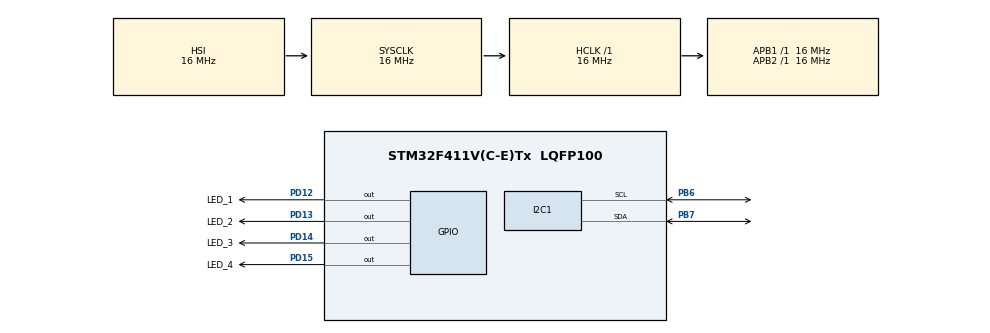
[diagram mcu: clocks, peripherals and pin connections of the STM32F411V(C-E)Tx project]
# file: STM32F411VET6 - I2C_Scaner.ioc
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Mcu.Family=STM32F4
Mcu.Name=STM32F411V(C-E)Tx
Mcu.Package=LQFP100
NVIC.PriorityGroup=NVIC_PRIORITYGROUP_4
PA13.Mode=Serial_Wire
PA13.Signal=SYS_JTMS-SWDIO
PA14.Mode=Serial_Wire
PA14.Signal=SYS_JTCK-SWCLK
PB6.Mode=I2C
PB6.Signal=I2C1_SCL
PB7.Mode=I2C
PB7.Signal=I2C1_SDA
PD12.GPIO_Label=LED_1
PD12.Signal=GPIO_Output
PD13.GPIO_Label=LED_2
PD13.Signal=GPIO_Output
PD14.GPIO_Label=LED_3
PD14.Signal=GPIO_Output
PD15.GPIO_Label=LED_4
PD15.Signal=GPIO_Output
ProjectManager.HeapSize=0x200
ProjectManager.StackSize=0x400
ProjectManager.TargetToolchain=STM32CubeIDE
RCC.AHBFreq_Value=16000000
RCC.APB1Freq_Value=16000000
RCC.APB2Freq_Value=16000000
RCC.CortexFreq_Value=16000000
RCC.HSE_VALUE=25000000
RCC.HSI_VALUE=16000000
RCC.LSE_VALUE=32768
RCC.SYSCLKFreq_VALUE=16000000
RCC.VCOOutputFreq_Value=192000000
board=custom

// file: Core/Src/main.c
/* USER CODE BEGIN Header */
/**
  ******************************************************************************
  * @file           : main.c
  * @brief          : Main program body
  ******************************************************************************
  * @attention
  *
  * Copyright (c) 2024 STMicroelectronics.
  * All rights reserved.
  *
  * This software is licensed under terms that can be found in the LICENSE file
  * in the root directory of this software component.
  * If no LICENSE file comes with this software, it is provided AS-IS.
  *
  ******************************************************************************
  */
/* USER CODE END Header */
#include "main.h"
#include "i2c.h"
#include "gpio.h"

/* USER CODE BEGIN PD */
//#define BMP280_ADDRESS 0x76
/* USER CODE END PD */

/* USER CODE BEGIN PV */

uint8_t Adress;
/* USER CODE END PV */

void SystemClock_Config(void);

int main(void)
{

  /* MCU Configuration--------------------------------------------------------*/

  /* Reset of all peripherals, Initializes the Flash interface and the Systick. */
  HAL_Init();

  /* Configure the system clock */
  SystemClock_Config();

  /* Initialize all configured peripherals */
  MX_GPIO_Init();
  MX_I2C1_Init();
  /* USER CODE BEGIN 2 */
  //BMP280_Init(&Bmp280, &hi2c1, BMP280_ADDRESS);
  //float Temp, Pressure;

	HAL_StatusTypeDef result;
   	uint8_t i;
   	for (i=1; i<128; i++)
   	{
   	  /*
   	   * the HAL wants a left aligned i2c address
   	   * &hi2c1 is the handle
   	   * (uint16_t)(i<<1) is the i2c address left aligned
   	   * retries 2
   	   * timeout 2
   	   */
   	  result = HAL_I2C_IsDeviceReady(&hi2c1, (uint16_t)(i<<1), 2, 2);
   	  if (result != HAL_OK) // HAL_ERROR or HAL_BUSY or HAL_TIMEOUT
   	  {
   		 HAL_GPIO_TogglePin(LED_1_GPIO_Port, LED_2_Pin);
   	  }
   	  if (result == HAL_OK)
   	  {
   		Adress = i;
   		 HAL_GPIO_TogglePin(LED_2_GPIO_Port, LED_3_Pin);
   	  }
   	}

HAL_Delay(3000);

  HAL_Delay(3000);
  /* USER CODE END 2 */

  /* Infinite loop */
  while (1)
  {

    /* USER CODE BEGIN 3 */

	 // HAL_GPIO_TogglePin(LED_1_GPIO_Port, LED_1_Pin);
	  //HAL_Delay(250);
	  //BMP280_ReadPressureAndTemperature(&Bmp280, &Pressure, &Temp);
	 // HAL_GPIO_TogglePin(LED_2_GPIO_Port, LED_2_Pin);
	 // HAL_Delay(250);

  }
  /* USER CODE END 3 */
}

void SystemClock_Config(void)
{
  RCC_OscInitTypeDef RCC_OscInitStruct = {0};
  RCC_ClkInitTypeDef RCC_ClkInitStruct = {0};

  /** Configure the main internal regulator output voltage
  */
  __HAL_RCC_PWR_CLK_ENABLE();
  __HAL_PWR_VOLTAGESCALING_CONFIG(PWR_REGULATOR_VOLTAGE_SCALE1);

  /** Initializes the RCC Oscillators according to the specified parameters
  * in the RCC_OscInitTypeDef structure.
  */
  RCC_OscInitStruct.OscillatorType = RCC_OSCILLATORTYPE_HSI;
  RCC_OscInitStruct.HSIState = RCC_HSI_ON;
  RCC_OscInitStruct.HSICalibrationValue = RCC_HSICALIBRATION_DEFAULT;
  RCC_OscInitStruct.PLL.PLLState = RCC_PLL_NONE;
  if (HAL_RCC_OscConfig(&RCC_OscInitStruct) != HAL_OK)
  {
    Error_Handler();
  }

  /** Initializes the CPU, AHB and APB buses clocks
  */
  RCC_ClkInitStruct.ClockType = RCC_CLOCKTYPE_HCLK|RCC_CLOCKTYPE_SYSCLK
                              |RCC_CLOCKTYPE_PCLK1|RCC_CLOCKTYPE_PCLK2;
  RCC_ClkInitStruct.SYSCLKSource = RCC_SYSCLKSOURCE_HSI;
  RCC_ClkInitStruct.AHBCLKDivider = RCC_SYSCLK_DIV1;
  RCC_ClkInitStruct.APB1CLKDivider = RCC_HCLK_DIV1;
  RCC_ClkInitStruct.APB2CLKDivider = RCC_HCLK_DIV1;

  if (HAL_RCC_ClockConfig(&RCC_ClkInitStruct, FLASH_LATENCY_0) != HAL_OK)
  {
    Error_Handler();
  }
}

void Error_Handler(void)
{
  __disable_irq();
  while (1)
  {
  }
}
